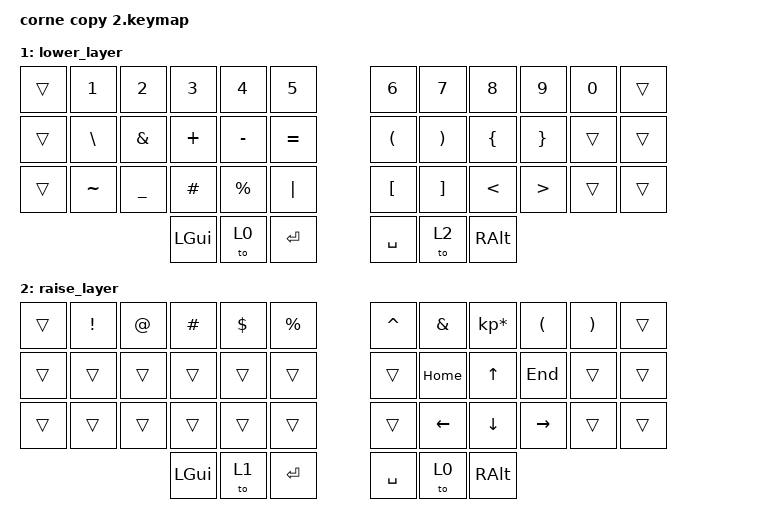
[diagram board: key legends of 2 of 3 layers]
/*
 * Copyright (c) 2020 The ZMK Contributors
 *
 * SPDX-License-Identifier: MIT
 */

#include <behaviors.dtsi>
#include <dt-bindings/zmk/keys.h>
#include <dt-bindings/zmk/bt.h>
#include <dt-bindings/zmk/outputs.h>
/ {
        keymap {
                compatible = "zmk,keymap";
                default_layer {
// ----------------------------------- QWERTY -------------------------------------------------
// | ESC  |  Q  |  W  |  E  |  R  |  T  |   |  Y  |  U   |  I  |  O  |  P  | BKSP |
// | TAB  |  A  |  S  |  D  |  F  |  G  |   |  H  |  J   |  K  |  L  |  ;  |  '   |
// | CTRL |  Z  |  X  |  C  |  V  |  B  |   |  N  |  M   |  ,  |  .  |  /  | ALT  |
//                    | GUI | LWR | ENT |   | SPC | RSE  | ALT |
                        bindings = <
   &kp ESC   &kp Q &kp W    &kp E    &kp R     &kp T      &kp Y     &kp U  &kp I     &kp O   &kp P    &kp BSPC
   &kp TAB   &kp A &kp S    &kp D    &kp F     &kp G      &kp H     &kp J  &kp K     &kp L   &kp SEMI &kp SQT
   &kp LCTRL &kp Z &kp X    &kp C    &kp V     &kp B      &kp N     &kp M  &kp COMMA &kp DOT &kp FSLH &kp LALT
                   &kp LGUI &to 1    &kp RET              &kp SPACE &to 2  &kp RSHFT 
                   &out OUT_BLE
                        >;
                };
                lower_layer {
// -----------------------------------------------------------------------------------------
// |      |  1  |  2  |  3  |  4  |  5  |   |  6  |  7  |  8  |  9  |  0  |      |
// |      |  \  |  *  |  +  |  -  |  =  |   |  (  |  )  |  {  |  }  |     |      |
// |      |  ~  |  _  |  #  |  %  | "|" |   |  [  |  ]  |  <  |  >  |     |      |
//                    | GUI |     | SPC |   | ENT | RSE | ALT |
                        bindings = <
   &trans    &kp N1       &kp N2       &kp N3       &kp N4       &kp N5         &kp N6    &kp N7   &kp N8   &kp N9   &kp N0 &trans
   &trans    &kp BSLH     &kp AMPS     &kp PLUS     &kp MINUS    &kp EQUAL      &kp LPAR  &kp RPAR &kp LBRC &kp RBRC &trans &trans
   &trans    &kp TILDE    &kp UNDER    &kp HASH     &kp PRCNT    &kp PIPE       &kp LBKT  &kp RBKT &kp LT   &kp GT   &trans &trans
                          	       &kp LGUI     &to 0        &kp RET        &kp SPACE &to 2    &kp RALT
                        >;
                };
 
                raise_layer {
// -----------------------------------------------------------------------------------------
// |      |  !  |  @  |  #  |  $  |  %  |   |  ^  |  &  |  *  |  (  |  )  |      |
// |      |     |     |     |     |     |   |     | HOME| UP  | END |     |      |
// |      |     |     |     |     |     |   |     | LFT | DWN | RGT |     |      |
//                    | GUI | LWR | SPC |   | ENT |     | ALT |
                        bindings = <
   &trans    &kp EXCL &kp AT &kp HASH &kp DLLR &kp PRCNT   &kp CARET &kp AMPS  &kp KP_MULTIPLY &kp LPAR  &kp RPAR &trans
   &trans    &trans   &trans &trans   &trans   &trans      &trans    &kp HOME  &kp UP          &kp END   &trans   &trans 
   &trans    &trans   &trans &trans   &trans   &trans      &trans    &kp LEFT  &kp DOWN        &kp RIGHT &trans   &trans
                    	     &kp LGUI &to 1    &kp RET     &kp SPACE &to 0     &kp RALT
                        >;
                };
        };
};
